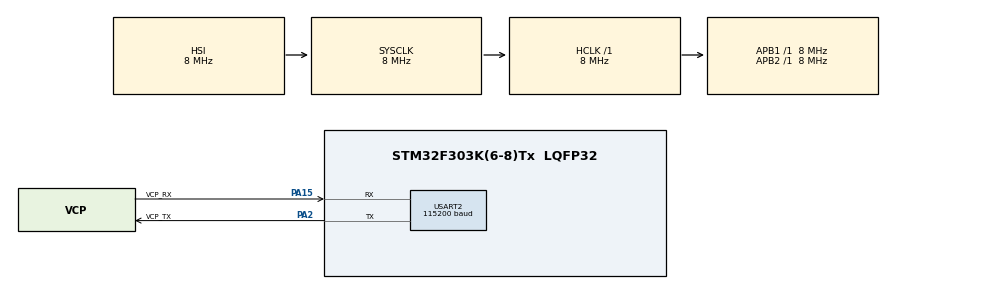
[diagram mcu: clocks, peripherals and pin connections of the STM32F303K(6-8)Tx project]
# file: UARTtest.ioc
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Mcu.Family=STM32F3
Mcu.Name=STM32F303K(6-8)Tx
Mcu.Package=LQFP32
NVIC.PriorityGroup=NVIC_PRIORITYGROUP_4
NVIC.USART2_IRQn=true\:0\:0\:false\:false\:true\:true
PA13.GPIO_Label=SWDIO
PA13.Signal=SYS_JTMS-SWDIO
PA14.GPIO_Label=SWCLK
PA14.Signal=SYS_JTCK-SWCLK
PA15.GPIO_Label=VCP_RX
PA15.Mode=Asynchronous
PA15.Signal=USART2_RX
PA2.GPIO_Label=VCP_TX
PA2.Mode=Asynchronous
PA2.Signal=USART2_TX
PF0\ /\ OSC_IN.GPIO_Label=MCO
PF0\ /\ OSC_IN.Signal=RCC_OSC_IN
ProjectManager.HeapSize=0x200
ProjectManager.StackSize=0x400
ProjectManager.TargetToolchain=SW4STM32
RCC.AHBFreq_Value=8000000
RCC.APB1Freq_Value=8000000
RCC.APB2Freq_Value=8000000
RCC.CortexFreq_Value=8000000
RCC.HSE_VALUE=8000000
RCC.HSI_VALUE=8000000
RCC.SYSCLKFreq_VALUE=8000000
USART2.BaudRate=115200
USART2.VirtualMode-Asynchronous=VM_ASYNC
USART2.WordLength=WORDLENGTH_8B
board=NUCLEO-F303K8

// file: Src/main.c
/**
  ******************************************************************************
  * File Name          : main.c
  * Description        : Main program body
  ******************************************************************************
  ** This notice applies to any and all portions of this file
  * that are not between comment pairs USER CODE BEGIN and
  * USER CODE END. Other portions of this file, whether
  * inserted by the user or by software development tools
  * are owned by their respective copyright owners.
  *
  * COPYRIGHT(c) 2018 STMicroelectronics
  *
  * Redistribution and use in source and binary forms, with or without modification,
  * are permitted provided that the following conditions are met:
  *   1. Redistributions of source code must retain the above copyright notice,
  *      this list of conditions and the following disclaimer.
  *   2. Redistributions in binary form must reproduce the above copyright notice,
  *      this list of conditions and the following disclaimer in the documentation
  *      and/or other materials provided with the distribution.
  *   3. Neither the name of STMicroelectronics nor the names of its contributors
  *      may be used to endorse or promote products derived from this software
  *      without specific prior written permission.
  *
  * THIS SOFTWARE IS PROVIDED BY THE COPYRIGHT HOLDERS AND CONTRIBUTORS "AS IS"
  * AND ANY EXPRESS OR IMPLIED WARRANTIES, INCLUDING, BUT NOT LIMITED TO, THE
  * IMPLIED WARRANTIES OF MERCHANTABILITY AND FITNESS FOR A PARTICULAR PURPOSE ARE
  * DISCLAIMED. IN NO EVENT SHALL THE COPYRIGHT HOLDER OR CONTRIBUTORS BE LIABLE
  * FOR ANY DIRECT, INDIRECT, INCIDENTAL, SPECIAL, EXEMPLARY, OR CONSEQUENTIAL
  * DAMAGES (INCLUDING, BUT NOT LIMITED TO, PROCUREMENT OF SUBSTITUTE GOODS OR
  * SERVICES; LOSS OF USE, DATA, OR PROFITS; OR BUSINESS INTERRUPTION) HOWEVER
  * CAUSED AND ON ANY THEORY OF LIABILITY, WHETHER IN CONTRACT, STRICT LIABILITY,
  * OR TORT (INCLUDING NEGLIGENCE OR OTHERWISE) ARISING IN ANY WAY OUT OF THE USE
  * OF THIS SOFTWARE, EVEN IF ADVISED OF THE POSSIBILITY OF SUCH DAMAGE.
  *
  ******************************************************************************
  */

#include "main.h"
#include "stm32f3xx_hal.h"

/* USER CODE BEGIN Includes */
#include "xprintf.h"
/* USER CODE END Includes */

UART_HandleTypeDef huart2;
/* USER CODE BEGIN PV */
/* Private variables ---------------------------------------------------------*/
uint8_t rxBuff[50];
uint8_t rxData;
uint16_t rxDataCount=0;
volatile unsigned int *DWT_CYCCNT = (volatile unsigned int *)0xE0001004; //address of the register
volatile unsigned int *DWT_CONTROL = (volatile unsigned int *)0xE0001000; //address of the register
volatile unsigned int *SCB_DEMCR = (volatile unsigned int *)0xE000EDFC; //address of the register
/* USER CODE END PV */

void SystemClock_Config(void);
static void MX_GPIO_Init(void);
static void MX_USART2_UART_Init(void);

/* USER CODE BEGIN PFP */
/* Private function prototypes -----------------------------------------------*/

/* USER CODE END PFP */

/* USER CODE BEGIN 0 */
#ifdef __GNUC__
#define PUTCHAR_PROTOTYPE int __io_putchar(int ch)
#else
#define PUTCHAR_PROTOTYPE int fputc(int ch, FILE *f)
#endif /* __GNUC__ */
void __io_putchar(uint8_t ch) {
	HAL_UART_Transmit(&huart2, &ch, 1, 1);
}
void EnableTiming(void){
	*SCB_DEMCR = *SCB_DEMCR | 0x01000000;
	*DWT_CYCCNT = 0; // reset the counter
	*DWT_CONTROL = *DWT_CONTROL | 1 ; // enable the counter
}

void TimingDelay(unsigned int tick){
	tick=tick*8;//マイコンのクロック準拠のため、マイコンのMHz倍が必要
	unsigned int start, current;
	start = *DWT_CYCCNT;
	do{
		current = *DWT_CYCCNT;
	} while((current - start) < tick);
}

void HAL_UART_RxCpltCallback(UART_HandleTypeDef *UartHandle){
	HAL_UART_Receive_IT(&huart2, &rxData, 1);
	//バッファに文字をため込む
	if(rxDataCount<sizeof(rxBuff)){
		rxBuff[rxDataCount]=rxData;
		rxDataCount++;
	}
	if(rxDataCount==sizeof(rxBuff)){
		rxDataCount=0;
	}

}
uint8_t uart_getc(void){
	uint8_t c=0;
	char buf[1];
	HAL_UART_Receive(&huart2,(uint8_t *)buf,sizeof(buf),0xFFFF);
	c=buf[0];
	return c;
}
void uart_putc(uint8_t c){
	char buf[1];
	buf[0]=c;
	HAL_UART_Transmit(&huart2,(uint8_t *)buf,sizeof(buf),0xFFFF);
}
void uart_puts(char *str){
	while(*str){
		uart_putc(*str++);
	}
}
uint8_t check_recieved_data(){
	//rxDataBuffにそれっぽいデータが入ってるか確認。チェックサムもここで確認
	//ヘッダのFFから
}
/* USER CODE END 0 */

int main(void)
{

  /* MCU Configuration----------------------------------------------------------*/

  /* Reset of all peripherals, Initializes the Flash interface and the Systick. */
  HAL_Init();

  /* Configure the system clock */
  SystemClock_Config();

  /* Initialize all configured peripherals */
  MX_GPIO_Init();
  MX_USART2_UART_Init();

  /* USER CODE BEGIN 2 */
  HAL_UART_Receive_IT(&huart2, &rxData, 1);
  xdev_out(uart_putc);
  setbuf(stdout, NULL);
  int count=0;
  uint8_t byte_T=0x54;
  EnableTiming();
  /* USER CODE END 2 */

  /* Infinite loop */
  /* USER CODE BEGIN WHILE */
  while (1){
	  check_recieved_data();
	  //HAL_Delay(1000);
	  //printf("char:%c byte:%x\n",byte_T,byte_T);
	  //count++;
	  TimingDelay(1000000);//1sec
	  printf("count:%d\n",count);
	  //printf("char:%c byte:%x\n",byte_T,byte_T);
	  count++;
  /* USER CODE END WHILE */

  }

}

/** System Clock Configuration
*/
void SystemClock_Config(void)
{

  RCC_OscInitTypeDef RCC_OscInitStruct;
  RCC_ClkInitTypeDef RCC_ClkInitStruct;

    /**Initializes the CPU, AHB and APB busses clocks
    */
  RCC_OscInitStruct.OscillatorType = RCC_OSCILLATORTYPE_HSI;
  RCC_OscInitStruct.HSIState = RCC_HSI_ON;
  RCC_OscInitStruct.HSICalibrationValue = 16;
  RCC_OscInitStruct.PLL.PLLState = RCC_PLL_NONE;
  if (HAL_RCC_OscConfig(&RCC_OscInitStruct) != HAL_OK)
  {
    _Error_Handler(__FILE__, __LINE__);
  }

    /**Initializes the CPU, AHB and APB busses clocks
    */
  RCC_ClkInitStruct.ClockType = RCC_CLOCKTYPE_HCLK|RCC_CLOCKTYPE_SYSCLK
                              |RCC_CLOCKTYPE_PCLK1|RCC_CLOCKTYPE_PCLK2;
  RCC_ClkInitStruct.SYSCLKSource = RCC_SYSCLKSOURCE_HSI;
  RCC_ClkInitStruct.AHBCLKDivider = RCC_SYSCLK_DIV1;
  RCC_ClkInitStruct.APB1CLKDivider = RCC_HCLK_DIV1;
  RCC_ClkInitStruct.APB2CLKDivider = RCC_HCLK_DIV1;

  if (HAL_RCC_ClockConfig(&RCC_ClkInitStruct, FLASH_LATENCY_0) != HAL_OK)
  {
    _Error_Handler(__FILE__, __LINE__);
  }

    /**Configure the Systick interrupt time
    */
  HAL_SYSTICK_Config(HAL_RCC_GetHCLKFreq()/1000);

    /**Configure the Systick
    */
  HAL_SYSTICK_CLKSourceConfig(SYSTICK_CLKSOURCE_HCLK);

  /* SysTick_IRQn interrupt configuration */
  HAL_NVIC_SetPriority(SysTick_IRQn, 0, 0);
}

/* USART2 init function */
static void MX_USART2_UART_Init(void)
{

  huart2.Instance = USART2;
  huart2.Init.BaudRate = 115200;
  huart2.Init.WordLength = UART_WORDLENGTH_8B;
  huart2.Init.StopBits = UART_STOPBITS_1;
  huart2.Init.Parity = UART_PARITY_NONE;
  huart2.Init.Mode = UART_MODE_TX_RX;
  huart2.Init.HwFlowCtl = UART_HWCONTROL_NONE;
  huart2.Init.OverSampling = UART_OVERSAMPLING_16;
  huart2.Init.OneBitSampling = UART_ONE_BIT_SAMPLE_DISABLE;
  huart2.AdvancedInit.AdvFeatureInit = UART_ADVFEATURE_NO_INIT;
  if (HAL_UART_Init(&huart2) != HAL_OK)
  {
    _Error_Handler(__FILE__, __LINE__);
  }

}

/** Configure pins as
        * Analog
        * Input
        * Output
        * EVENT_OUT
        * EXTI
*/
static void MX_GPIO_Init(void)
{

  /* GPIO Ports Clock Enable */
  __HAL_RCC_GPIOF_CLK_ENABLE();
  __HAL_RCC_GPIOA_CLK_ENABLE();

}

void _Error_Handler(char * file, int line)
{
  while(1)
  {
  }
}

/************************ (C) COPYRIGHT STMicroelectronics *****END OF FILE****/
